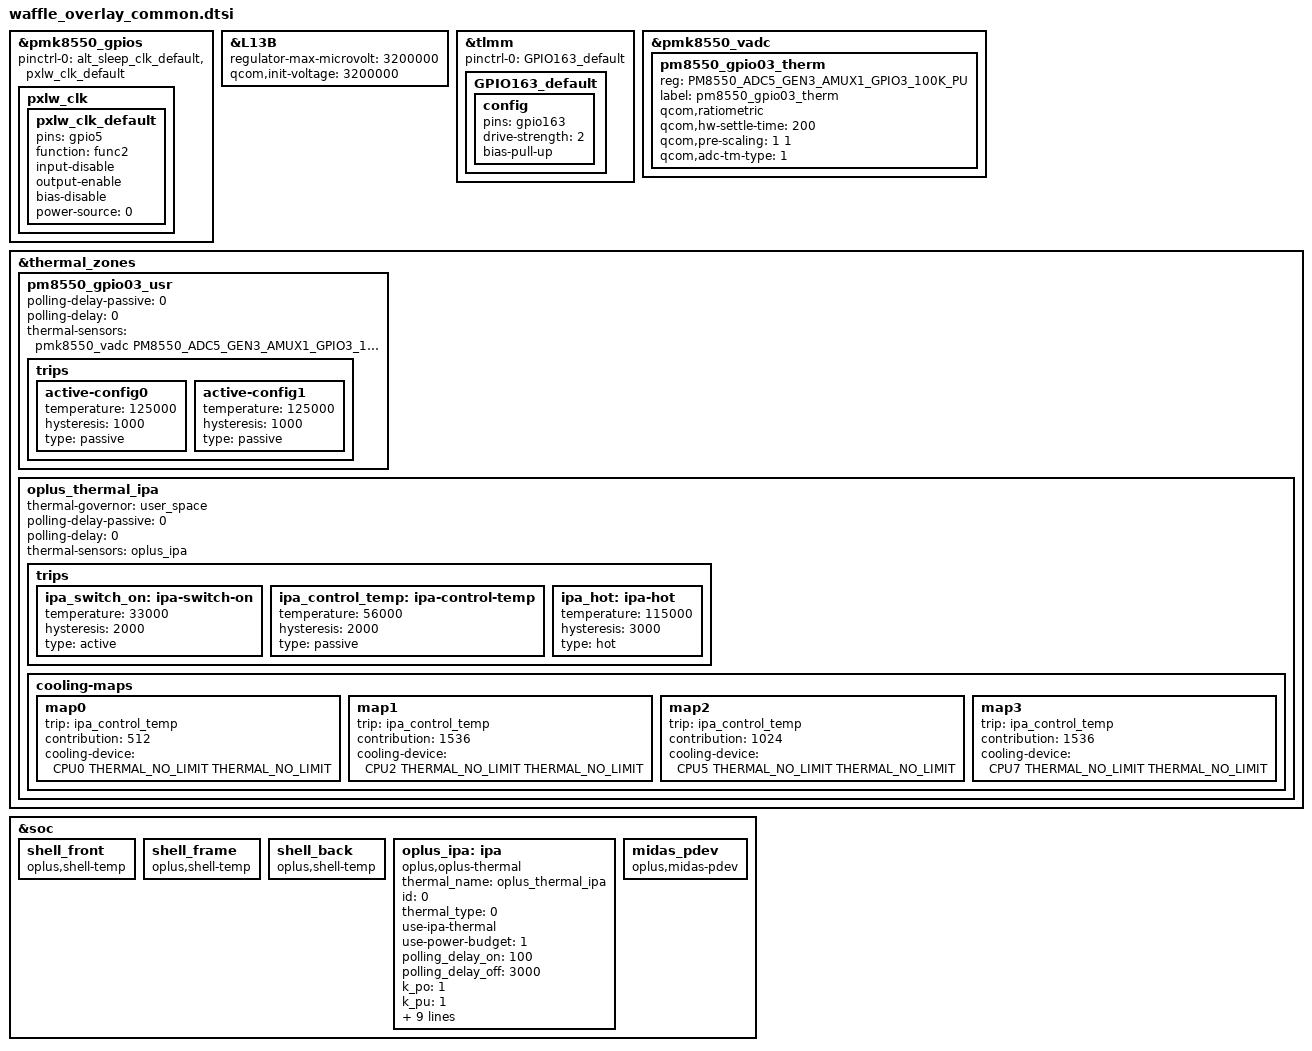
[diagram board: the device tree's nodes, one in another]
//#if defined(PXLW_IRIS)
&pmk8550_gpios {
	/delete-property/ pinctrl-0;
	pinctrl-0 = <&alt_sleep_clk_default &pxlw_clk_default>;
	pinctrl-names = "default";

	pxlw_clk {
		pxlw_clk_default: pxlw_clk_default {
			pins = "gpio5";
			function = "func2";
			input-disable;
			output-enable;
			bias-disable;
			power-source = <0>;
		};
	};
};
//#endif /* PXLW_IRIS */

//#ifdef OPLUS_FEATURE_DISPLAY
&L13B {
	regulator-max-microvolt = <3200000>;
	qcom,init-voltage = <3200000>;
};
&tlmm {
	pinctrl-names = "default";
	pinctrl-0 = <&GPIO163_default>;

	GPIO163_default: GPIO163_default {
		config {
			pins = "gpio163";
			drive-strength = <2>;
			bias-pull-up;
		};
	};
};
//#endif /* OPLUS_FEATURE_DISPLAY */

&pmk8550_vadc {
	pm8550_gpio03_therm {
		reg = <PM8550_ADC5_GEN3_AMUX1_GPIO3_100K_PU>;
		label = "pm8550_gpio03_therm";
		qcom,ratiometric;
		qcom,hw-settle-time = <200>;
		qcom,pre-scaling = <1 1>;
		qcom,adc-tm-type = <1>;
	};
};

&thermal_zones {
	pm8550_gpio03_usr {
		polling-delay-passive = <0>;
		polling-delay = <0>;
		thermal-sensors = <&pmk8550_vadc PM8550_ADC5_GEN3_AMUX1_GPIO3_100K_PU>;
		trips {
			active-config0 {
				temperature = <125000>;
				hysteresis = <1000>;
				type = "passive";
			};
			active-config1 {
				temperature = <125000>;
				hysteresis = <1000>;
				type = "passive";
			};
		};
	};

	oplus_thermal_ipa {
		thermal-governor = "user_space";
		polling-delay-passive = <0>;
		polling-delay = <0>;
		thermal-sensors = <&oplus_ipa>;
		trips {
			ipa_switch_on: ipa-switch-on {
				temperature = <33000>;
				hysteresis = <2000>;
				type = "active";
			};
			ipa_control_temp: ipa-control-temp {
				temperature = <56000>;
				hysteresis = <2000>;
				type = "passive";
			};
			ipa_hot: ipa-hot {
				temperature = <115000>;
				hysteresis = <3000>;
				type = "hot";
			};
		};
		cooling-maps {
			map0 {
				trip = <&ipa_control_temp>;
				contribution = <512>;
				cooling-device = <&CPU0 THERMAL_NO_LIMIT THERMAL_NO_LIMIT>;
			};
			map1 {
				trip = <&ipa_control_temp>;
				contribution = <1536>;
				cooling-device = <&CPU2 THERMAL_NO_LIMIT THERMAL_NO_LIMIT>;
			};
			map2 {
				trip = <&ipa_control_temp>;
				contribution = <1024>;
				cooling-device = <&CPU5 THERMAL_NO_LIMIT THERMAL_NO_LIMIT>;
			};
			map3 {
				trip = <&ipa_control_temp>;
				contribution = <1536>;
				cooling-device = <&CPU7 THERMAL_NO_LIMIT THERMAL_NO_LIMIT>;
			};
		};
	};
};
&soc {
	//#ifdef OPLUS_FEATURE_THERMAL_HORAE
	shell_front {
		compatible = "oplus,shell-temp";
	};

	shell_frame {
		compatible = "oplus,shell-temp";
	};

	shell_back {
		compatible = "oplus,shell-temp";
	};
	//#endif /* OPLUS_FEATURE_THERMAL_HORAE */

	oplus_ipa: ipa {
		compatible = "oplus,oplus-thermal";
		thermal_name = "oplus_thermal_ipa";
		id = <0>;
		thermal_type = <0>;
		#thermal-sensor-cells = <0>;
		use-ipa-thermal;
		use-power-budget = <1>;
		polling_delay_on = <100>;
		polling_delay_off = <3000>;
		k_po = <1>;
		k_pu = <1>;
		k_i = <1>;
		k_d = <0>;
		i_max = <2>;
		integral_cutoff = <10>;
		sustainable_power = <9999>;
		thermal_work_affinity = "0-8";
		cdev_min_power = <230 200 350 90 0 0>;
		use-thermalcontrol-limit = <1>;
		clt_state_limit = <0 0 0 0 0 0>;
	};
	midas_pdev {
		compatible = "oplus,midas-pdev";
	};
};
